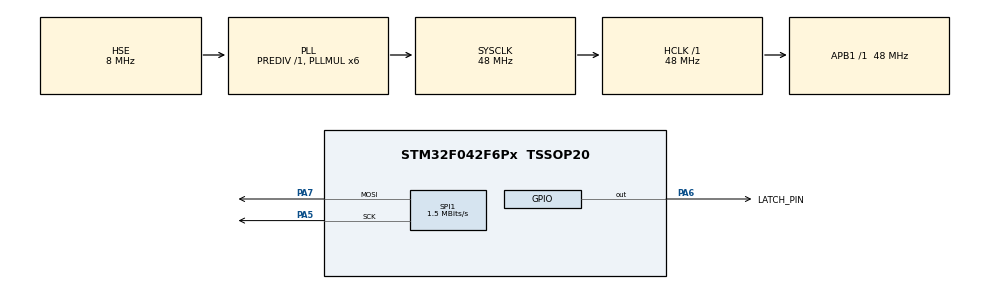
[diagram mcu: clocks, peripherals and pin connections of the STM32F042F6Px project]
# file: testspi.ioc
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Mcu.Family=STM32F0
Mcu.Name=STM32F042F6Px
Mcu.Package=TSSOP20
PA13.Mode=Serial_Wire
PA13.Signal=SYS_SWDIO
PA14.Mode=Serial_Wire
PA14.Signal=SYS_SWCLK
PA5.Mode=TX_Only_Simplex_Unidirect_Master
PA5.Signal=SPI1_SCK
PA6.GPIO_Label=LATCH_PIN
PA6.GPIO_PuPd=GPIO_NOPULL
PA6.GPIO_Speed=GPIO_SPEED_FREQ_HIGH
PA6.Signal=GPIO_Output
PA7.Mode=TX_Only_Simplex_Unidirect_Master
PA7.Signal=SPI1_MOSI
PF0-OSC_IN.Mode=HSE-External-Oscillator
PF0-OSC_IN.Signal=RCC_OSC_IN
PF1-OSC_OUT.Mode=HSE-External-Oscillator
PF1-OSC_OUT.Signal=RCC_OSC_OUT
ProjectManager.HeapSize=0x200
ProjectManager.StackSize=0x400
ProjectManager.TargetToolchain=STM32CubeIDE
RCC.AHBFreq_Value=48000000
RCC.APB1Freq_Value=48000000
RCC.APB1TimFreq_Value=48000000
RCC.HCLKFreq_Value=48000000
RCC.PLLMUL=RCC_PLL_MUL6
RCC.PLLSourceVirtual=RCC_PLLSOURCE_HSE
RCC.SYSCLKFreq_VALUE=48000000
RCC.SYSCLKSource=RCC_SYSCLKSOURCE_PLLCLK
SPI1.BaudRatePrescaler=SPI_BAUDRATEPRESCALER_32
SPI1.CLKPolarity=SPI_POLARITY_LOW
SPI1.CalculateBaudRate=1.5 MBits/s
SPI1.DataSize=SPI_DATASIZE_8BIT
SPI1.Direction=SPI_DIRECTION_2LINES
SPI1.Mode=SPI_MODE_MASTER
SPI1.NSSPMode=SPI_NSS_PULSE_DISABLE
SPI1.TIMode=SPI_TIMODE_DISABLE
SPI1.VirtualNSS=VM_NSSHARD
SPI1.VirtualType=VM_MASTER
board=custom

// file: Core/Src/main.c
/* USER CODE BEGIN Header */
/**
  ******************************************************************************
  * @file           : main.c
  * @brief          : Main program body
  ******************************************************************************
  * @attention
  *
  * Copyright (c) 2022 STMicroelectronics.
  * All rights reserved.
  *
  * This software is licensed under terms that can be found in the LICENSE file
  * in the root directory of this software component.
  * If no LICENSE file comes with this software, it is provided AS-IS.
  *
  ******************************************************************************
  */
/* USER CODE END Header */
#include "main.h"

/* USER CODE BEGIN PD */
#define delay 500
#define time 200
/* USER CODE END PD */

 SPI_HandleTypeDef hspi1;

/* USER CODE BEGIN PV */
uint8_t dat0[9] = {0xff,0x01,0x01,0x01,0x01,0x01,0x01,0x01,0x01};
uint8_t dat1[9] = {0x01,0xff,0xff,0xff,0xff,0xff,0xff,0xff,0xff};
uint8_t dataCube[9];
/* USER CODE END PV */

void SystemClock_Config(void);
static void MX_GPIO_Init(void);
static void MX_SPI1_Init(void);
/* USER CODE BEGIN PFP */
void TransmitData(uint8_t* data, uint16_t size, uint32_t timeout );
void clearCube();
void planeCube();
void lightCube();
void waveCube();
/* USER CODE END PFP */

/* USER CODE BEGIN 0 */
void TransmitData(uint8_t* data, uint16_t size, uint32_t timeout )
{
	HAL_GPIO_WritePin(LATCH_PIN_GPIO_Port, LATCH_PIN_Pin, GPIO_PIN_RESET);
	HAL_SPI_Transmit(&hspi1, data, size, timeout);
	HAL_GPIO_WritePin(LATCH_PIN_GPIO_Port, LATCH_PIN_Pin, GPIO_PIN_SET);
};

void clearCube()
{
	uint8_t data[9];
	for (int i = 0; i < 9; i++)
	{
		data[i] = 0x00;
	}
	TransmitData(data, 9, 100);
};

void planeCube()
{
	uint8_t dataCube0[9] = {0xff,0xff,0xff,0xff,0xff,0xff,0xff,0xff,0xff};
	TransmitData(dataCube0, 9, 100);
	HAL_Delay(time);
	uint8_t dataCube1[9] = {0x7e,0x00,0x7e,0x7e,0x7e,0x7e,0x7e,0x7e,0x00};
	TransmitData(dataCube1, 9, 100);
	HAL_Delay(time);
	uint8_t dataCube2[9] = {0x3c,0x00,0x00,0x3c,0x3c,0x3c,0x3c,0x00,0x00};
	TransmitData(dataCube2, 9, 100);
	HAL_Delay(time);
	uint8_t dataCube3[9] = {0x18,0x00,0x00,0x00,0x18,0x18,0x00,0x00,0x00};
	TransmitData(dataCube3, 9, 100);
	HAL_Delay(time);
	uint8_t dataCube4[9] = {0x00,0x00,0x00,0x00,0x00,0x00,0x00,0x00,0x00};
	TransmitData(dataCube4, 9, 100);
	HAL_Delay(time);
	TransmitData(dataCube4, 9, 100);
	HAL_Delay(time);
	TransmitData(dataCube3, 9, 100);
	TransmitData(dataCube2, 9, 100);
	HAL_Delay(time);
	TransmitData(dataCube1, 9, 100);
	HAL_Delay(time);
	TransmitData(dataCube0, 9, 100);
	HAL_Delay(time);
};

void lightCube()
{
	uint8_t data[9];
	for (int i = 0; i < 9; i++)
	{
		data[i] = 0xff;
	}
	TransmitData(data, 9, 100);
};

void waveCube()
{

}
/* USER CODE END 0 */

int main(void)
{

  /* MCU Configuration--------------------------------------------------------*/

  /* Reset of all peripherals, Initializes the Flash interface and the Systick. */
  HAL_Init();

  /* Configure the system clock */
  SystemClock_Config();

  /* Initialize all configured peripherals */
  MX_GPIO_Init();
  MX_SPI1_Init();

  /* Infinite loop */
  while (1)
  {

    /* USER CODE BEGIN 3 */
	  planeCube();
  }
  /* USER CODE END 3 */
}

void SystemClock_Config(void)
{
  RCC_OscInitTypeDef RCC_OscInitStruct = {0};
  RCC_ClkInitTypeDef RCC_ClkInitStruct = {0};

  /** Initializes the RCC Oscillators according to the specified parameters
  * in the RCC_OscInitTypeDef structure.
  */
  RCC_OscInitStruct.OscillatorType = RCC_OSCILLATORTYPE_HSE;
  RCC_OscInitStruct.HSEState = RCC_HSE_ON;
  RCC_OscInitStruct.PLL.PLLState = RCC_PLL_ON;
  RCC_OscInitStruct.PLL.PLLSource = RCC_PLLSOURCE_HSE;
  RCC_OscInitStruct.PLL.PLLMUL = RCC_PLL_MUL6;
  RCC_OscInitStruct.PLL.PREDIV = RCC_PREDIV_DIV1;
  if (HAL_RCC_OscConfig(&RCC_OscInitStruct) != HAL_OK)
  {
    Error_Handler();
  }

  /** Initializes the CPU, AHB and APB buses clocks
  */
  RCC_ClkInitStruct.ClockType = RCC_CLOCKTYPE_HCLK|RCC_CLOCKTYPE_SYSCLK
                              |RCC_CLOCKTYPE_PCLK1;
  RCC_ClkInitStruct.SYSCLKSource = RCC_SYSCLKSOURCE_PLLCLK;
  RCC_ClkInitStruct.AHBCLKDivider = RCC_SYSCLK_DIV1;
  RCC_ClkInitStruct.APB1CLKDivider = RCC_HCLK_DIV1;

  if (HAL_RCC_ClockConfig(&RCC_ClkInitStruct, FLASH_LATENCY_1) != HAL_OK)
  {
    Error_Handler();
  }
}

static void MX_SPI1_Init(void)
{

  /* SPI1 parameter configuration*/
  hspi1.Instance = SPI1;
  hspi1.Init.Mode = SPI_MODE_MASTER;
  hspi1.Init.Direction = SPI_DIRECTION_2LINES;
  hspi1.Init.DataSize = SPI_DATASIZE_8BIT;
  hspi1.Init.CLKPolarity = SPI_POLARITY_LOW;
  hspi1.Init.CLKPhase = SPI_PHASE_1EDGE;
  hspi1.Init.NSS = SPI_NSS_SOFT;
  hspi1.Init.BaudRatePrescaler = SPI_BAUDRATEPRESCALER_32;
  hspi1.Init.FirstBit = SPI_FIRSTBIT_MSB;
  hspi1.Init.TIMode = SPI_TIMODE_DISABLE;
  hspi1.Init.CRCCalculation = SPI_CRCCALCULATION_DISABLE;
  hspi1.Init.CRCPolynomial = 7;
  hspi1.Init.CRCLength = SPI_CRC_LENGTH_DATASIZE;
  hspi1.Init.NSSPMode = SPI_NSS_PULSE_DISABLE;
  if (HAL_SPI_Init(&hspi1) != HAL_OK)
  {
    Error_Handler();
  }

}

static void MX_GPIO_Init(void)
{
  GPIO_InitTypeDef GPIO_InitStruct = {0};

  /* GPIO Ports Clock Enable */
  __HAL_RCC_GPIOF_CLK_ENABLE();
  __HAL_RCC_GPIOA_CLK_ENABLE();

  /*Configure GPIO pin Output Level */
  HAL_GPIO_WritePin(LATCH_PIN_GPIO_Port, LATCH_PIN_Pin, GPIO_PIN_RESET);

  /*Configure GPIO pin : LATCH_PIN_Pin */
  GPIO_InitStruct.Pin = LATCH_PIN_Pin;
  GPIO_InitStruct.Mode = GPIO_MODE_OUTPUT_PP;
  GPIO_InitStruct.Pull = GPIO_NOPULL;
  GPIO_InitStruct.Speed = GPIO_SPEED_FREQ_HIGH;
  HAL_GPIO_Init(LATCH_PIN_GPIO_Port, &GPIO_InitStruct);

}

void Error_Handler(void)
{
  __disable_irq();
  while (1)
  {
  }
}
